# STM8L001J3 register map
Vendor: STMicroelectronics; Series: STM8L101, low density; File version: 1.0
CPU: other r1p0, big endian, no MPU, no FPU, 4 interrupt priority bits
Registers are 8-bit, read-write, reset 0x0 unless marked. A register's access mark holds for its fields unless they carry their own. Offsets are from the block's base; [hi:lo] are bit positions; {n}, {i} and the like mark numbered series.

## PORTC
Base 0x0000500A
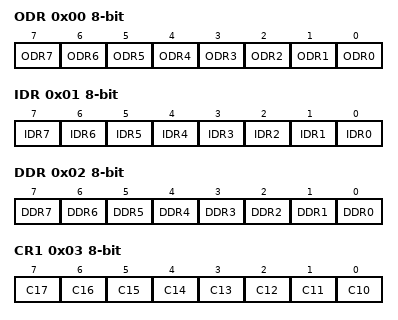
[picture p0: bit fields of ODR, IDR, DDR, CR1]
0x00 ODR — Port C data output latch register
  [n] ODR{n} (n=0..7)
0x01 IDR — Port C input pin value register
  [n] IDR{n} (n=0..7)
0x02 DDR — Port C data direction register
  [n] DDR{n} (n=0..7)
0x03 CR1 — Port C control register 1
  [n-10] C{n} (n=10..17)
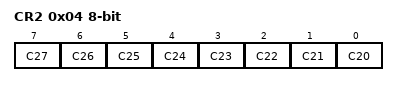
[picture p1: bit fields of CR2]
0x04 CR2 — Port C control register 2
  [n-20] C{n} (n=20..27)

## PORTD
Base 0x0000500F
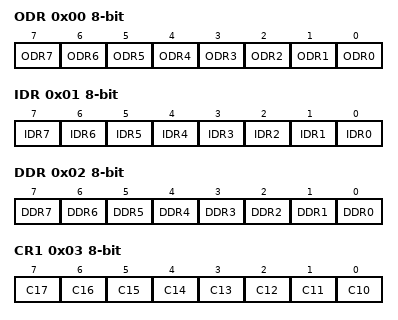
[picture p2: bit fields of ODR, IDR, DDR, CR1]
0x00 ODR — Port D data output latch register
  [n] ODR{n} (n=0..7)
0x01 IDR — Port D input pin value register
  [n] IDR{n} (n=0..7)
0x02 DDR — Port D data direction register
  [n] DDR{n} (n=0..7)
0x03 CR1 — Port D control register 1
  [n-10] C{n} (n=10..17)
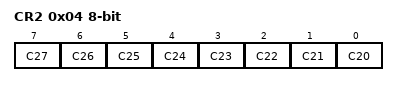
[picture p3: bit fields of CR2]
0x04 CR2 — Port D control register 2
  [n-20] C{n} (n=20..27)

## RST
Base 0x000050B0
0x00 CR — Reset control register
  [7:0] RSTPIN_KEY
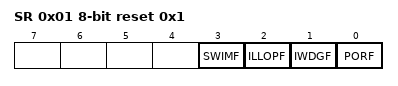
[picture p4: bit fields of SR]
0x01 SR reset 0x1 — Reset status register
  [3] SWIMF, [2] ILLOPF, [1] IWDGF, [0] PORF

## SPI
Base 0x00005200
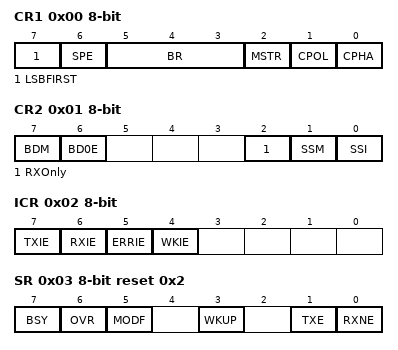
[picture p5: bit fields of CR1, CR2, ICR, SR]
0x00 CR1 — SPI control register 1
  [7] LSBFIRST, [6] SPE, [5:3] BR, [2] MSTR, [1] CPOL, [0] CPHA
0x01 CR2 — SPI control register 2
  [7] BDM, [6] BD0E, [2] RXOnly, [1] SSM, [0] SSI
0x02 ICR — SPI interrupt control register
  [7] TXIE, [6] RXIE, [5] ERRIE, [4] WKIE
0x03 SR reset 0x2 — SPI status register
  [7] BSY, [6] OVR, [5] MODF, [3] WKUP, [1] TXE, [0] RXNE
0x04 DR — SPI data register

## SWIM
Base 0x00007F80
0x00 CSR — SWIM control status register

## TIM2
Base 0x00005250
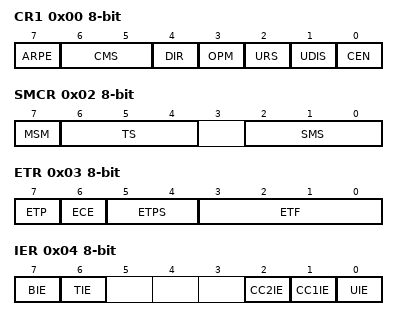
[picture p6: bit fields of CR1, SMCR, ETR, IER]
0x00 CR1 — TIM2 Control register 1
  [7] ARPE, [6:5] CMS, [4] DIR, [3] OPM, [2] URS, [1] UDIS, [0] CEN
0x01 CR2 — TIM2 Control register 2
  [6:4] MMS
0x02 SMCR — TIM2 Slave Mode Control register
  [7] MSM, [6:4] TS, [2:0] SMS
0x03 ETR — TIM2 external trigger register
  [7] ETP, [6] ECE, [5:4] ETPS, [3:0] ETF
0x04 IER — TIM2 Interrupt enable register
  [7] BIE, [6] TIE, [2] CC2IE, [1] CC1IE, [0] UIE
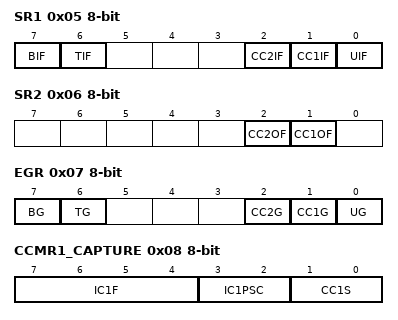
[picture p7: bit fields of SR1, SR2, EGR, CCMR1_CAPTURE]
0x05 SR1 — TIM2 Status register 1
  [7] BIF, [6] TIF, [2] CC2IF, [1] CC1IF, [0] UIF
0x06 SR2 — TIM2 Status register 2
  [2] CC2OF, [1] CC1OF
0x07 EGR — TIM2 Event Generation register
  [7] BG, [6] TG, [2] CC2G, [1] CC1G, [0] UG
0x08 CCMR1_CAPTURE — TIM2 Capture/Compare mode register 1
  [7:4] IC1F, [3:2] IC1PSC, [1:0] CC1S
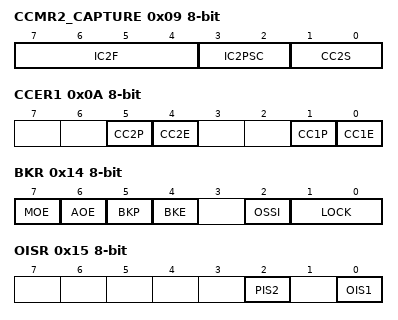
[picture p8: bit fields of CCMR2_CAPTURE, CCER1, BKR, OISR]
0x09 CCMR2_CAPTURE — TIM2 Capture/Compare mode register 2
  [7:4] IC2F, [3:2] IC2PSC, [1:0] CC2S
0x0A CCER1 — TIM2 Capture/Compare enable register 1
  [5] CC2P, [4] CC2E, [1] CC1P, [0] CC1E
0x0B CNTRH — TIM2 Counter high
  [7:0] CNT
0x0C CNTRL — TIM2 Counter low
  [7:0] CNT
0x0D PSCR — TIM2 Prescaler register
  [2:0] PSC
0x0E ARRH reset 0xFF — TIM2 Auto-reload register high
  [7:0] ARR
0x0F ARRL reset 0xFF — TIM2 Auto-reload register low
  [7:0] ARR
0x10 CCR1H — TIM2 Capture/Compare register 1 high
  [7:0] CCR
0x11 CCR1L — TIM2 Capture/Compare register 1 low
  [7:0] CCR
0x12 CCR2H — TIM2 Capture/Compare register 2 high
  [7:0] CCR2
0x13 CCR2L — TIM2 Capture/Compare register 2 low
  [7:0] CCR2
0x14 BKR — TIM2 Break register
  [7] MOE, [6] AOE, [5] BKP, [4] BKE, [2] OSSI, [1:0] LOCK
0x15 OISR — TIM2 Output idle state register
  [2] PIS2, [0] OIS1

## TIM3
Base 0x00005280
Registers as TIM2 (with TIM2 read as TIM3).

## TIM4
Base 0x000052E0
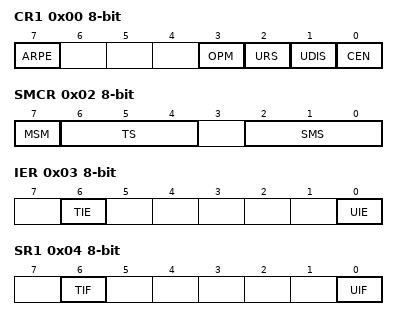
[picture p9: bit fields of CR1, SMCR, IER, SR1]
0x00 CR1 — TIM4 Control register 1
  [7] ARPE, [3] OPM, [2] URS, [1] UDIS, [0] CEN
0x01 CR2 — TIM4 Control register 2
  [6:4] MMS
0x02 SMCR — TIM4 Slave Mode Control Register
  [7] MSM, [6:4] TS, [2:0] SMS
0x03 IER — TIM4 Interrupt enable register
  [6] TIE, [0] UIE
0x04 SR1 — TIM4 Status register 1
  [6] TIF, [0] UIF
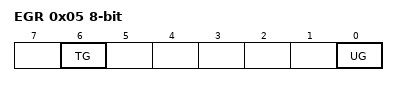
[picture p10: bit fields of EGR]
0x05 EGR — TIM4 Event Generation register
  [6] TG, [0] UG
0x06 CNTR — TIM4 Counter
  [7:0] CNT
0x07 PSCR — TIM4 Prescaler register
  [3:0] PSC
0x08 ARR reset 0xFF — TIM4 Auto-reload register low

## USART
Base 0x00005230
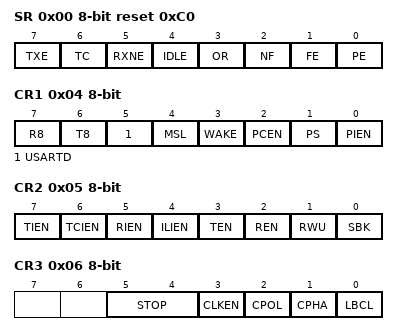
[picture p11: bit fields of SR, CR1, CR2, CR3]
0x00 SR reset 0xC0 — USART Status Register
  [7] TXE, [6] TC, [5] RXNE, [4] IDLE, [3] OR, [2] NF, [1] FE, [0] PE
0x01 DR — USART Data Register
0x02 BRR1 — USART Baud Rate Register 1
  [7:0] USART_DIV
0x03 BRR2 — USART Baud Rate Register 2
  [7:0] USART_DIV
0x04 CR1 — USART Control Register 1
  [7] R8, [6] T8, [5] USARTD, [4] MSL, [3] WAKE, [2] PCEN, [1] PS, [0] PIEN
0x05 CR2 — USART Control Register 2
  [7] TIEN, [6] TCIEN, [5] RIEN, [4] ILIEN, [3] TEN, [2] REN, [1] RWU, [0] SBK
0x06 CR3 — USART Control Register 3
  [5:4] STOP, [3] CLKEN, [2] CPOL, [1] CPHA, [0] LBCL
0x07 CR4 — USART Control Register 4
  [3:0] ADD

## WFE
Base 0x000050A6
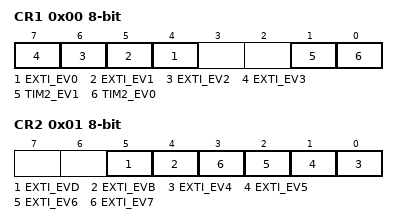
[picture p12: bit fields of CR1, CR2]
0x00 CR1 — WFE control register 1
  [n+4] EXTI_EV{n} (n=0..3), [1] TIM2_EV1, [0] TIM2_EV0
0x01 CR2 — WFE control register 2
  [5] EXTI_EVD, [4] EXTI_EVB, [n-4] EXTI_EV{n} (n=4..7)
